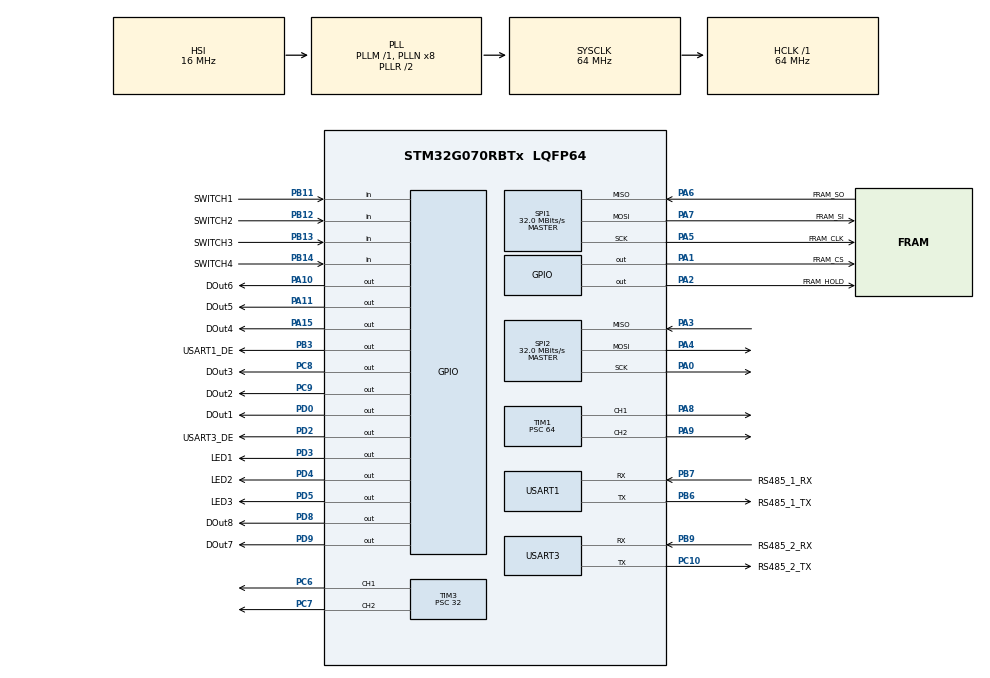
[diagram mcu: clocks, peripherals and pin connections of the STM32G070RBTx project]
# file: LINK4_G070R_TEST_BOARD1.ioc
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Mcu.Family=STM32G0
Mcu.Name=STM32G070RBTx
Mcu.Package=LQFP64
NVIC.TIM6_IRQn=true\:0\:0\:false\:false\:true\:true\:true\:true
NVIC.USART3_4_IRQn=true\:0\:0\:false\:false\:true\:true\:true\:true
PA0.Mode=Full_Duplex_Master
PA0.Signal=SPI2_SCK
PA1.GPIO_Label=FRAM_CS
PA1.Signal=GPIO_Output
PA10.GPIO_Label=DOut6
PA10.Signal=GPIO_Output
PA11\ [PA9].GPIO_Label=DOut5
PA11\ [PA9].Signal=GPIO_Output
PA13.Mode=Serial_Wire
PA13.Signal=SYS_SWDIO
PA14-BOOT0.Mode=Serial_Wire
PA14-BOOT0.Signal=SYS_SWCLK
PA15.GPIO_Label=DOut4
PA15.Signal=GPIO_Output
PA2.GPIO_Label=FRAM_HOLD
PA2.Signal=GPIO_Output
PA3.Mode=Full_Duplex_Master
PA3.Signal=SPI2_MISO
PA4.Mode=Full_Duplex_Master
PA4.Signal=SPI2_MOSI
PA5.GPIO_Label=FRAM_CLK
PA5.Mode=Full_Duplex_Master
PA5.Signal=SPI1_SCK
PA6.GPIO_Label=FRAM_SO
PA6.Mode=Full_Duplex_Master
PA6.Signal=SPI1_MISO
PA7.GPIO_Label=FRAM_SI
PA7.Mode=Full_Duplex_Master
PA7.Signal=SPI1_MOSI
PA8.Signal=S_TIM1_CH1
PA9.Signal=S_TIM1_CH2
PB11.GPIO_Label=SWITCH1
PB11.GPIO_PuPd=GPIO_PULLUP
PB11.Signal=GPIO_Input
PB12.GPIO_Label=SWITCH2
PB12.GPIO_PuPd=GPIO_PULLUP
PB12.Signal=GPIO_Input
PB13.GPIO_Label=SWITCH3
PB13.GPIO_PuPd=GPIO_PULLUP
PB13.Signal=GPIO_Input
PB14.GPIO_Label=SWITCH4
PB14.GPIO_PuPd=GPIO_PULLUP
PB14.Signal=GPIO_Input
PB3.GPIO_Label=USART1_DE
PB3.Signal=GPIO_Output
PB6.GPIO_Label=RS485_1_TX
PB6.Mode=Asynchronous
PB6.Signal=USART1_TX
PB7.GPIO_Label=RS485_1_RX
PB7.Mode=Asynchronous
PB7.Signal=USART1_RX
PB9.GPIO_Label=RS485_2_RX
PB9.Mode=Asynchronous
PB9.Signal=USART3_RX
PC10.GPIO_Label=RS485_2_TX
PC10.Mode=Asynchronous
PC10.Signal=USART3_TX
PC6.Signal=S_TIM3_CH1
PC7.Signal=S_TIM3_CH2
PC8.GPIO_Label=DOut3
PC8.Signal=GPIO_Output
PC9.GPIO_Label=DOut2
PC9.Signal=GPIO_Output
PD0.GPIO_Label=DOut1
PD0.Signal=GPIO_Output
PD2.GPIO_Label=USART3_DE
PD2.Signal=GPIO_Output
PD3.GPIO_Label=LED1
PD3.Signal=GPIO_Output
PD4.GPIO_Label=LED2
PD4.Signal=GPIO_Output
PD5.GPIO_Label=LED3
PD5.Signal=GPIO_Output
PD8.GPIO_Label=DOut8
PD8.Signal=GPIO_Output
PD9.GPIO_Label=DOut7
PD9.Signal=GPIO_Output
PF0-OSC_IN\ (PF0).Mode=HSE-External-Oscillator
PF0-OSC_IN\ (PF0).Signal=RCC_OSC_IN
PF1-OSC_OUT\ (PF1).Mode=HSE-External-Oscillator
PF1-OSC_OUT\ (PF1).Signal=RCC_OSC_OUT
ProjectManager.HeapSize=0x200
ProjectManager.StackSize=0x400
ProjectManager.TargetToolchain=STM32CubeIDE
RCC.ADCFreq_Value=64000000
RCC.AHBFreq_Value=64000000
RCC.CortexFreq_Value=64000000
RCC.EXTERNAL_CLOCK_VALUE=48000
RCC.HCLKFreq_Value=64000000
RCC.HSE_VALUE=8000000
RCC.HSI_VALUE=16000000
RCC.LSE_VALUE=32768
RCC.SYSCLKFreq_VALUE=64000000
RCC.SYSCLKSource=RCC_SYSCLKSOURCE_PLLCLK
RCC.VCOOutputFreq_Value=128000000
SH.S_TIM1_CH1.0=TIM1_CH1,PWM Generation1 CH1
SH.S_TIM1_CH2.0=TIM1_CH2,PWM Generation2 CH2
SH.S_TIM3_CH1.0=TIM3_CH1,PWM Generation1 CH1
SH.S_TIM3_CH2.0=TIM3_CH2,PWM Generation2 CH2
SPI1.BaudRatePrescaler=SPI_BAUDRATEPRESCALER_2
SPI1.CalculateBaudRate=32.0 MBits/s
SPI1.Direction=SPI_DIRECTION_2LINES
SPI1.Mode=SPI_MODE_MASTER
SPI1.VirtualType=VM_MASTER
SPI2.BaudRatePrescaler=SPI_BAUDRATEPRESCALER_2
SPI2.CalculateBaudRate=32.0 MBits/s
SPI2.Direction=SPI_DIRECTION_2LINES
SPI2.Mode=SPI_MODE_MASTER
SPI2.VirtualType=VM_MASTER
TIM1.Channel-PWM\ Generation1\ CH1=TIM_CHANNEL_1
TIM1.Channel-PWM\ Generation2\ CH2=TIM_CHANNEL_2
TIM1.Period=999
TIM1.Prescaler=64
TIM1.Pulse-PWM\ Generation1\ CH1=250
TIM1.Pulse-PWM\ Generation2\ CH2=500
TIM3.Channel-PWM\ Generation1\ CH1=TIM_CHANNEL_1
TIM3.Channel-PWM\ Generation2\ CH2=TIM_CHANNEL_2
TIM3.Period=999
TIM3.Prescaler=32
TIM3.Pulse-PWM\ Generation1\ CH1=250
TIM3.Pulse-PWM\ Generation2\ CH2=500
TIM6.AutoReloadPreload=TIM_AUTORELOAD_PRELOAD_ENABLE
TIM6.Prescaler=64
USART1.VirtualMode-Asynchronous=VM_ASYNC
USART3.VirtualMode-Asynchronous=VM_ASYNC
VP_CRC_VS_CRC.Mode=CRC_Activate
VP_SYS_VS_DBSignals.Mode=DisableDeadBatterySignals
VP_TIM1_VS_ClockSourceINT.Mode=Internal
VP_TIM3_VS_ClockSourceINT.Mode=Internal
VP_TIM6_VS_ClockSourceINT.Mode=Enable_Timer
board=custom

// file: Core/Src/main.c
/* USER CODE BEGIN Header */
/**
  ******************************************************************************
  * @file           : main.c
  * @brief          : Main program body
  ******************************************************************************
  * @attention
  *
  * Copyright (c) 2022 STMicroelectronics.
  * All rights reserved.
  *
  * This software is licensed under terms that can be found in the LICENSE file
  * in the root directory of this software component.
  * If no LICENSE file comes with this software, it is provided AS-IS.
  *
  ******************************************************************************
  */
/* USER CODE END Header */
#include "main.h"

/* USER CODE BEGIN Includes */
#include "ConMain.h"
/* USER CODE END Includes */

SPI_HandleTypeDef hspi1;
SPI_HandleTypeDef hspi2;

TIM_HandleTypeDef htim1;
TIM_HandleTypeDef htim3;
TIM_HandleTypeDef htim6;

UART_HandleTypeDef huart1;
UART_HandleTypeDef huart3;

void SystemClock_Config(void);
static void MX_GPIO_Init(void);
static void MX_USART1_UART_Init(void);
static void MX_USART3_UART_Init(void);
static void MX_SPI1_Init(void);
static void MX_SPI2_Init(void);
static void MX_TIM1_Init(void);
static void MX_TIM3_Init(void);
static void MX_TIM6_Init(void);
static void MX_CRC_Init(void);

int main(void)
{

  /* MCU Configuration--------------------------------------------------------*/

  /* Reset of all peripherals, Initializes the Flash interface and the Systick. */
  HAL_Init();

  /* Configure the system clock */
  SystemClock_Config();

  /* Initialize all configured peripherals */
  MX_GPIO_Init();
  MX_USART1_UART_Init();
  MX_USART3_UART_Init();
  MX_SPI1_Init();
  MX_SPI2_Init();
  MX_TIM1_Init();
  MX_TIM3_Init();
  MX_TIM6_Init();
  MX_CRC_Init();
  /* USER CODE BEGIN 2 */

  ContextInit();
  ContextMain();

  /* USER CODE END 2 */

  /* Infinite loop */
  while (1)
  {

  }
}

void SystemClock_Config(void)
{
  RCC_OscInitTypeDef RCC_OscInitStruct = {0};
  RCC_ClkInitTypeDef RCC_ClkInitStruct = {0};

  /** Configure the main internal regulator output voltage
  */
  HAL_PWREx_ControlVoltageScaling(PWR_REGULATOR_VOLTAGE_SCALE1);

  /** Initializes the RCC Oscillators according to the specified parameters
  * in the RCC_OscInitTypeDef structure.
  */
  RCC_OscInitStruct.OscillatorType = RCC_OSCILLATORTYPE_HSI;
  RCC_OscInitStruct.HSIState = RCC_HSI_ON;
  RCC_OscInitStruct.HSIDiv = RCC_HSI_DIV1;
  RCC_OscInitStruct.HSICalibrationValue = RCC_HSICALIBRATION_DEFAULT;
  RCC_OscInitStruct.PLL.PLLState = RCC_PLL_ON;
  RCC_OscInitStruct.PLL.PLLSource = RCC_PLLSOURCE_HSI;
  RCC_OscInitStruct.PLL.PLLM = RCC_PLLM_DIV1;
  RCC_OscInitStruct.PLL.PLLN = 8;
  RCC_OscInitStruct.PLL.PLLP = RCC_PLLP_DIV2;
  RCC_OscInitStruct.PLL.PLLR = RCC_PLLR_DIV2;
  if (HAL_RCC_OscConfig(&RCC_OscInitStruct) != HAL_OK)
  {
    Error_Handler();
  }

  /** Initializes the CPU, AHB and APB buses clocks
  */
  RCC_ClkInitStruct.ClockType = RCC_CLOCKTYPE_HCLK|RCC_CLOCKTYPE_SYSCLK
                              |RCC_CLOCKTYPE_PCLK1;
  RCC_ClkInitStruct.SYSCLKSource = RCC_SYSCLKSOURCE_PLLCLK;
  RCC_ClkInitStruct.AHBCLKDivider = RCC_SYSCLK_DIV1;
  RCC_ClkInitStruct.APB1CLKDivider = RCC_HCLK_DIV1;

  if (HAL_RCC_ClockConfig(&RCC_ClkInitStruct, FLASH_LATENCY_2) != HAL_OK)
  {
    Error_Handler();
  }
}

static void MX_CRC_Init(void)
{

  /* Peripheral clock enable */
  LL_AHB1_GRP1_EnableClock(LL_AHB1_GRP1_PERIPH_CRC);

  LL_CRC_SetInputDataReverseMode(CRC, LL_CRC_INDATA_REVERSE_NONE);
  LL_CRC_SetOutputDataReverseMode(CRC, LL_CRC_OUTDATA_REVERSE_NONE);
  LL_CRC_SetPolynomialCoef(CRC, LL_CRC_DEFAULT_CRC32_POLY);
  LL_CRC_SetPolynomialSize(CRC, LL_CRC_POLYLENGTH_32B);
  LL_CRC_SetInitialData(CRC, LL_CRC_DEFAULT_CRC_INITVALUE);

}

static void MX_SPI1_Init(void)
{

  /* SPI1 parameter configuration*/
  hspi1.Instance = SPI1;
  hspi1.Init.Mode = SPI_MODE_MASTER;
  hspi1.Init.Direction = SPI_DIRECTION_2LINES;
  hspi1.Init.DataSize = SPI_DATASIZE_4BIT;
  hspi1.Init.CLKPolarity = SPI_POLARITY_LOW;
  hspi1.Init.CLKPhase = SPI_PHASE_1EDGE;
  hspi1.Init.NSS = SPI_NSS_SOFT;
  hspi1.Init.BaudRatePrescaler = SPI_BAUDRATEPRESCALER_2;
  hspi1.Init.FirstBit = SPI_FIRSTBIT_MSB;
  hspi1.Init.TIMode = SPI_TIMODE_DISABLE;
  hspi1.Init.CRCCalculation = SPI_CRCCALCULATION_DISABLE;
  hspi1.Init.CRCPolynomial = 7;
  hspi1.Init.CRCLength = SPI_CRC_LENGTH_DATASIZE;
  hspi1.Init.NSSPMode = SPI_NSS_PULSE_ENABLE;
  if (HAL_SPI_Init(&hspi1) != HAL_OK)
  {
    Error_Handler();
  }

}

static void MX_SPI2_Init(void)
{

  /* SPI2 parameter configuration*/
  hspi2.Instance = SPI2;
  hspi2.Init.Mode = SPI_MODE_MASTER;
  hspi2.Init.Direction = SPI_DIRECTION_2LINES;
  hspi2.Init.DataSize = SPI_DATASIZE_4BIT;
  hspi2.Init.CLKPolarity = SPI_POLARITY_LOW;
  hspi2.Init.CLKPhase = SPI_PHASE_1EDGE;
  hspi2.Init.NSS = SPI_NSS_SOFT;
  hspi2.Init.BaudRatePrescaler = SPI_BAUDRATEPRESCALER_2;
  hspi2.Init.FirstBit = SPI_FIRSTBIT_MSB;
  hspi2.Init.TIMode = SPI_TIMODE_DISABLE;
  hspi2.Init.CRCCalculation = SPI_CRCCALCULATION_DISABLE;
  hspi2.Init.CRCPolynomial = 7;
  hspi2.Init.CRCLength = SPI_CRC_LENGTH_DATASIZE;
  hspi2.Init.NSSPMode = SPI_NSS_PULSE_ENABLE;
  if (HAL_SPI_Init(&hspi2) != HAL_OK)
  {
    Error_Handler();
  }

}

static void MX_TIM1_Init(void)
{

  TIM_ClockConfigTypeDef sClockSourceConfig = {0};
  TIM_MasterConfigTypeDef sMasterConfig = {0};
  TIM_OC_InitTypeDef sConfigOC = {0};
  TIM_BreakDeadTimeConfigTypeDef sBreakDeadTimeConfig = {0};

  htim1.Instance = TIM1;
  htim1.Init.Prescaler = 64;
  htim1.Init.CounterMode = TIM_COUNTERMODE_UP;
  htim1.Init.Period = 999;
  htim1.Init.ClockDivision = TIM_CLOCKDIVISION_DIV1;
  htim1.Init.RepetitionCounter = 0;
  htim1.Init.AutoReloadPreload = TIM_AUTORELOAD_PRELOAD_DISABLE;
  if (HAL_TIM_Base_Init(&htim1) != HAL_OK)
  {
    Error_Handler();
  }
  sClockSourceConfig.ClockSource = TIM_CLOCKSOURCE_INTERNAL;
  if (HAL_TIM_ConfigClockSource(&htim1, &sClockSourceConfig) != HAL_OK)
  {
    Error_Handler();
  }
  if (HAL_TIM_PWM_Init(&htim1) != HAL_OK)
  {
    Error_Handler();
  }
  sMasterConfig.MasterOutputTrigger = TIM_TRGO_RESET;
  sMasterConfig.MasterOutputTrigger2 = TIM_TRGO2_RESET;
  sMasterConfig.MasterSlaveMode = TIM_MASTERSLAVEMODE_DISABLE;
  if (HAL_TIMEx_MasterConfigSynchronization(&htim1, &sMasterConfig) != HAL_OK)
  {
    Error_Handler();
  }
  sConfigOC.OCMode = TIM_OCMODE_PWM1;
  sConfigOC.Pulse = 250;
  sConfigOC.OCPolarity = TIM_OCPOLARITY_HIGH;
  sConfigOC.OCNPolarity = TIM_OCNPOLARITY_HIGH;
  sConfigOC.OCFastMode = TIM_OCFAST_DISABLE;
  sConfigOC.OCIdleState = TIM_OCIDLESTATE_RESET;
  sConfigOC.OCNIdleState = TIM_OCNIDLESTATE_RESET;
  if (HAL_TIM_PWM_ConfigChannel(&htim1, &sConfigOC, TIM_CHANNEL_1) != HAL_OK)
  {
    Error_Handler();
  }
  sConfigOC.Pulse = 500;
  if (HAL_TIM_PWM_ConfigChannel(&htim1, &sConfigOC, TIM_CHANNEL_2) != HAL_OK)
  {
    Error_Handler();
  }
  sBreakDeadTimeConfig.OffStateRunMode = TIM_OSSR_DISABLE;
  sBreakDeadTimeConfig.OffStateIDLEMode = TIM_OSSI_DISABLE;
  sBreakDeadTimeConfig.LockLevel = TIM_LOCKLEVEL_OFF;
  sBreakDeadTimeConfig.DeadTime = 0;
  sBreakDeadTimeConfig.BreakState = TIM_BREAK_DISABLE;
  sBreakDeadTimeConfig.BreakPolarity = TIM_BREAKPOLARITY_HIGH;
  sBreakDeadTimeConfig.BreakFilter = 0;
  sBreakDeadTimeConfig.BreakAFMode = TIM_BREAK_AFMODE_INPUT;
  sBreakDeadTimeConfig.Break2State = TIM_BREAK2_DISABLE;
  sBreakDeadTimeConfig.Break2Polarity = TIM_BREAK2POLARITY_HIGH;
  sBreakDeadTimeConfig.Break2Filter = 0;
  sBreakDeadTimeConfig.Break2AFMode = TIM_BREAK_AFMODE_INPUT;
  sBreakDeadTimeConfig.AutomaticOutput = TIM_AUTOMATICOUTPUT_DISABLE;
  if (HAL_TIMEx_ConfigBreakDeadTime(&htim1, &sBreakDeadTimeConfig) != HAL_OK)
  {
    Error_Handler();
  }
  HAL_TIM_MspPostInit(&htim1);

}

static void MX_TIM3_Init(void)
{

  TIM_ClockConfigTypeDef sClockSourceConfig = {0};
  TIM_MasterConfigTypeDef sMasterConfig = {0};
  TIM_OC_InitTypeDef sConfigOC = {0};

  htim3.Instance = TIM3;
  htim3.Init.Prescaler = 32;
  htim3.Init.CounterMode = TIM_COUNTERMODE_UP;
  htim3.Init.Period = 999;
  htim3.Init.ClockDivision = TIM_CLOCKDIVISION_DIV1;
  htim3.Init.AutoReloadPreload = TIM_AUTORELOAD_PRELOAD_DISABLE;
  if (HAL_TIM_Base_Init(&htim3) != HAL_OK)
  {
    Error_Handler();
  }
  sClockSourceConfig.ClockSource = TIM_CLOCKSOURCE_INTERNAL;
  if (HAL_TIM_ConfigClockSource(&htim3, &sClockSourceConfig) != HAL_OK)
  {
    Error_Handler();
  }
  if (HAL_TIM_PWM_Init(&htim3) != HAL_OK)
  {
    Error_Handler();
  }
  sMasterConfig.MasterOutputTrigger = TIM_TRGO_RESET;
  sMasterConfig.MasterSlaveMode = TIM_MASTERSLAVEMODE_DISABLE;
  if (HAL_TIMEx_MasterConfigSynchronization(&htim3, &sMasterConfig) != HAL_OK)
  {
    Error_Handler();
  }
  sConfigOC.OCMode = TIM_OCMODE_PWM1;
  sConfigOC.Pulse = 250;
  sConfigOC.OCPolarity = TIM_OCPOLARITY_HIGH;
  sConfigOC.OCFastMode = TIM_OCFAST_DISABLE;
  if (HAL_TIM_PWM_ConfigChannel(&htim3, &sConfigOC, TIM_CHANNEL_1) != HAL_OK)
  {
    Error_Handler();
  }
  sConfigOC.Pulse = 500;
  if (HAL_TIM_PWM_ConfigChannel(&htim3, &sConfigOC, TIM_CHANNEL_2) != HAL_OK)
  {
    Error_Handler();
  }
  HAL_TIM_MspPostInit(&htim3);

}

static void MX_TIM6_Init(void)
{

  TIM_MasterConfigTypeDef sMasterConfig = {0};

  htim6.Instance = TIM6;
  htim6.Init.Prescaler = 64;
  htim6.Init.CounterMode = TIM_COUNTERMODE_UP;
  htim6.Init.Period = 65535;
  htim6.Init.AutoReloadPreload = TIM_AUTORELOAD_PRELOAD_ENABLE;
  if (HAL_TIM_Base_Init(&htim6) != HAL_OK)
  {
    Error_Handler();
  }
  sMasterConfig.MasterOutputTrigger = TIM_TRGO_RESET;
  sMasterConfig.MasterSlaveMode = TIM_MASTERSLAVEMODE_DISABLE;
  if (HAL_TIMEx_MasterConfigSynchronization(&htim6, &sMasterConfig) != HAL_OK)
  {
    Error_Handler();
  }

}

static void MX_USART1_UART_Init(void)
{

  huart1.Instance = USART1;
  huart1.Init.BaudRate = 115200;
  huart1.Init.WordLength = UART_WORDLENGTH_8B;
  huart1.Init.StopBits = UART_STOPBITS_1;
  huart1.Init.Parity = UART_PARITY_NONE;
  huart1.Init.Mode = UART_MODE_TX_RX;
  huart1.Init.HwFlowCtl = UART_HWCONTROL_NONE;
  huart1.Init.OverSampling = UART_OVERSAMPLING_16;
  huart1.Init.OneBitSampling = UART_ONE_BIT_SAMPLE_DISABLE;
  huart1.Init.ClockPrescaler = UART_PRESCALER_DIV1;
  huart1.AdvancedInit.AdvFeatureInit = UART_ADVFEATURE_NO_INIT;
  if (HAL_UART_Init(&huart1) != HAL_OK)
  {
    Error_Handler();
  }
  if (HAL_UARTEx_SetTxFifoThreshold(&huart1, UART_TXFIFO_THRESHOLD_1_8) != HAL_OK)
  {
    Error_Handler();
  }
  if (HAL_UARTEx_SetRxFifoThreshold(&huart1, UART_RXFIFO_THRESHOLD_1_8) != HAL_OK)
  {
    Error_Handler();
  }
  if (HAL_UARTEx_DisableFifoMode(&huart1) != HAL_OK)
  {
    Error_Handler();
  }

}

static void MX_USART3_UART_Init(void)
{

  huart3.Instance = USART3;
  huart3.Init.BaudRate = 115200;
  huart3.Init.WordLength = UART_WORDLENGTH_8B;
  huart3.Init.StopBits = UART_STOPBITS_1;
  huart3.Init.Parity = UART_PARITY_NONE;
  huart3.Init.Mode = UART_MODE_TX_RX;
  huart3.Init.HwFlowCtl = UART_HWCONTROL_NONE;
  huart3.Init.OverSampling = UART_OVERSAMPLING_16;
  huart3.Init.OneBitSampling = UART_ONE_BIT_SAMPLE_DISABLE;
  huart3.Init.ClockPrescaler = UART_PRESCALER_DIV1;
  huart3.AdvancedInit.AdvFeatureInit = UART_ADVFEATURE_NO_INIT;
  if (HAL_UART_Init(&huart3) != HAL_OK)
  {
    Error_Handler();
  }

}

static void MX_GPIO_Init(void)
{
  GPIO_InitTypeDef GPIO_InitStruct = {0};

  /* GPIO Ports Clock Enable */
  __HAL_RCC_GPIOF_CLK_ENABLE();
  __HAL_RCC_GPIOA_CLK_ENABLE();
  __HAL_RCC_GPIOB_CLK_ENABLE();
  __HAL_RCC_GPIOC_CLK_ENABLE();
  __HAL_RCC_GPIOD_CLK_ENABLE();

  /*Configure GPIO pin Output Level */
  HAL_GPIO_WritePin(GPIOA, FRAM_CS_Pin|FRAM_HOLD_Pin|DOut6_Pin|DOut5_Pin
                          |DOut4_Pin, GPIO_PIN_RESET);

  /*Configure GPIO pin Output Level */
  HAL_GPIO_WritePin(GPIOD, DOut8_Pin|DOut7_Pin|DOut1_Pin|USART3_DE_Pin
                          |LED1_Pin|LED2_Pin|LED3_Pin, GPIO_PIN_RESET);

  /*Configure GPIO pin Output Level */
  HAL_GPIO_WritePin(GPIOC, DOut3_Pin|DOut2_Pin, GPIO_PIN_RESET);

  /*Configure GPIO pin Output Level */
  HAL_GPIO_WritePin(USART1_DE_GPIO_Port, USART1_DE_Pin, GPIO_PIN_RESET);

  /*Configure GPIO pins : FRAM_CS_Pin FRAM_HOLD_Pin DOut6_Pin DOut5_Pin
                           DOut4_Pin */
  GPIO_InitStruct.Pin = FRAM_CS_Pin|FRAM_HOLD_Pin|DOut6_Pin|DOut5_Pin
                          |DOut4_Pin;
  GPIO_InitStruct.Mode = GPIO_MODE_OUTPUT_PP;
  GPIO_InitStruct.Pull = GPIO_NOPULL;
  GPIO_InitStruct.Speed = GPIO_SPEED_FREQ_LOW;
  HAL_GPIO_Init(GPIOA, &GPIO_InitStruct);

  /*Configure GPIO pins : SWITCH1_Pin SWITCH2_Pin SWITCH3_Pin SWITCH4_Pin */
  GPIO_InitStruct.Pin = SWITCH1_Pin|SWITCH2_Pin|SWITCH3_Pin|SWITCH4_Pin;
  GPIO_InitStruct.Mode = GPIO_MODE_INPUT;
  GPIO_InitStruct.Pull = GPIO_PULLUP;
  HAL_GPIO_Init(GPIOB, &GPIO_InitStruct);

  /*Configure GPIO pins : DOut8_Pin DOut7_Pin DOut1_Pin USART3_DE_Pin
                           LED1_Pin LED2_Pin LED3_Pin */
  GPIO_InitStruct.Pin = DOut8_Pin|DOut7_Pin|DOut1_Pin|USART3_DE_Pin
                          |LED1_Pin|LED2_Pin|LED3_Pin;
  GPIO_InitStruct.Mode = GPIO_MODE_OUTPUT_PP;
  GPIO_InitStruct.Pull = GPIO_NOPULL;
  GPIO_InitStruct.Speed = GPIO_SPEED_FREQ_LOW;
  HAL_GPIO_Init(GPIOD, &GPIO_InitStruct);

  /*Configure GPIO pins : DOut3_Pin DOut2_Pin */
  GPIO_InitStruct.Pin = DOut3_Pin|DOut2_Pin;
  GPIO_InitStruct.Mode = GPIO_MODE_OUTPUT_PP;
  GPIO_InitStruct.Pull = GPIO_NOPULL;
  GPIO_InitStruct.Speed = GPIO_SPEED_FREQ_LOW;
  HAL_GPIO_Init(GPIOC, &GPIO_InitStruct);

  /*Configure GPIO pin : USART1_DE_Pin */
  GPIO_InitStruct.Pin = USART1_DE_Pin;
  GPIO_InitStruct.Mode = GPIO_MODE_OUTPUT_PP;
  GPIO_InitStruct.Pull = GPIO_NOPULL;
  GPIO_InitStruct.Speed = GPIO_SPEED_FREQ_LOW;
  HAL_GPIO_Init(USART1_DE_GPIO_Port, &GPIO_InitStruct);

}

void Error_Handler(void)
{
  __disable_irq();
  while (1)
  {
  }
}
